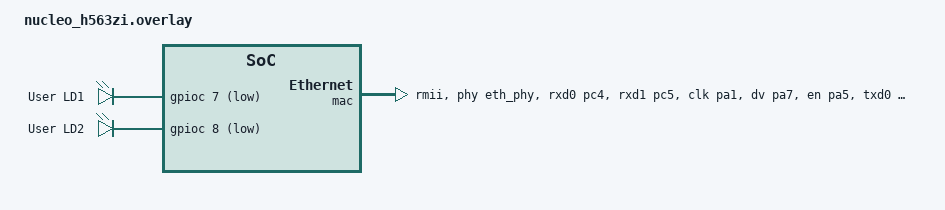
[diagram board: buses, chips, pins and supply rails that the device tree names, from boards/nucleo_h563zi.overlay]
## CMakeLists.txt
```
# SPDX-License-Identifier: Apache-2.0

cmake_minimum_required(VERSION 3.20.0)

find_package(Zephyr REQUIRED HINTS $ENV{ZEPHYR_BASE})
project(z_pub)

FILE(GLOB app_sources src/*.c)
target_sources(app PRIVATE ${app_sources})
```

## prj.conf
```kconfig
# printf, printk output to RTT
CONFIG_USE_SEGGER_RTT=y
CONFIG_RTT_CONSOLE=y
CONFIG_UART_CONSOLE=n
#CONFIG_SEGGER_RTT_MODE_NO_BLOCK_TRIM=y
#CONFIG_SEGGER_RTT_BUFFER_SIZE_UP=4096
#CONFIG_SEGGER_RTT_SECTION_CUSTOM_DTS_REGION=y

#
CONFIG_GPIO=y

# Increase stack size to 4096 bytes, otherwise it will crash with "Stack overflow in thread main"
CONFIG_MAIN_STACK_SIZE=4096
CONFIG_HEAP_MEM_POOL_SIZE=32768
CONFIG_POSIX_API=y

# Networking config
CONFIG_NETWORKING=y
CONFIG_NET_IPV4=y
CONFIG_NET_IPV6=y
CONFIG_NET_TCP=y
CONFIG_NET_UDP=y
CONFIG_NET_SOCKETS=y
CONFIG_NET_IPV4_MAPPING_TO_IPV6=y
CONFIG_NET_IPV4_IGMP=y

# Network address config
CONFIG_NET_CONFIG_SETTINGS=y
CONFIG_NET_CONFIG_NEED_IPV4=y
CONFIG_NET_CONFIG_NEED_IPV6=y
CONFIG_NET_CONFIG_MY_IPV4_ADDR="192.0.2.1"
CONFIG_NET_CONFIG_PEER_IPV4_ADDR="192.0.2.2"
CONFIG_NET_CONFIG_MY_IPV6_ADDR="2001:db8::1"
CONFIG_NET_CONFIG_PEER_IPV6_ADDR="2001:db8::2"

# zenoh-pico
CONFIG_ZENOH_PICO=y
```

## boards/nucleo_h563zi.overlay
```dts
/ {
	aliases {
		led0 = &green_led_1;
        led1 = &red_led_1;
	};
};

&clk_hse {
	status = "disabled";
};

&clk_hsi {
	status = "okay";
};

&pll {
	status = "disabled";
};

&rcc {
	clocks = <&clk_hsi>;
	clock-frequency = <64000000>;
};

&leds {
    green_led_1: led_1 {
        gpios = <&gpioc 7 GPIO_ACTIVE_LOW>;
        label = "User LD1";
    };

	yellow_led_1: led_2 {
		status = "disabled";
	};

    red_led_1: led_3 {
        gpios = <&gpioc 8 GPIO_ACTIVE_LOW>;
        label = "User LD2";
    };
};

&mac {
	status = "okay";
	pinctrl-0 = <&eth_rxd0_pc4
		     &eth_rxd1_pc5
		     &eth_ref_clk_pa1
		     &eth_crs_dv_pa7
		     &eth_tx_en_pa5
		     &eth_txd0_pb12
		     &eth_txd1_pb15>;
	pinctrl-names = "default";
	phy-connection-type = "rmii";
	phy-handle = <&eth_phy>;
};
```

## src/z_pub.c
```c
//
// Copyright (c) 2022 ZettaScale Technology
//
// This program and the accompanying materials are made available under the
// terms of the Eclipse Public License 2.0 which is available at
// http://www.eclipse.org/legal/epl-2.0, or the Apache License, Version 2.0
// which is available at https://www.apache.org/licenses/LICENSE-2.0.
//
// SPDX-License-Identifier: EPL-2.0 OR Apache-2.0
//
// Contributors:
//   ZettaScale Zenoh Team, <zenoh@zettascale.tech>

#include <stdio.h>
#include <stdlib.h>
#include <string.h>
#include <unistd.h>
#include <zenoh-pico.h>

#define CLIENT_OR_PEER 0  // 0: Client mode; 1: Peer mode
#if CLIENT_OR_PEER == 0
#define MODE "client"
//#define LOCATOR ""  // If empty, it will scout
#define LOCATOR "tcp/192.0.2.2:7447"
#elif CLIENT_OR_PEER == 1
#define MODE "peer"
#define LOCATOR "udp/224.0.0.225:7447#iface=en0"
#else
#error "Unknown Zenoh operation mode. Check CLIENT_OR_PEER value."
#endif

#define KEYEXPR "demo/example/zenoh-pico-pub"
#define VALUE CONFIG_BOARD_TARGET" Pub from Zenoh-Pico!"

#if Z_FEATURE_PUBLICATION == 1
int main(int argc, char **argv) {
    sleep(5);

    // Initialize Zenoh Session and other parameters
    z_owned_config_t config;
    z_config_default(&config);
    zp_config_insert(z_loan_mut(config), Z_CONFIG_MODE_KEY, MODE);
    if (strcmp(LOCATOR, "") != 0) {
        if (strcmp(MODE, "client") == 0) {
            zp_config_insert(z_loan_mut(config), Z_CONFIG_CONNECT_KEY, LOCATOR);
        } else {
            zp_config_insert(z_loan_mut(config), Z_CONFIG_LISTEN_KEY, LOCATOR);
        }
    }

    // Open Zenoh session
    printf("Opening Zenoh Session...");
    z_owned_session_t s;
    if (z_open(&s, z_move(config), NULL) < 0) {
        printf("Unable to open session!\n");
        return -1;
    }
    printf("OK\n");

    // Start the receive and the session lease loop for zenoh-pico
    zp_start_read_task(z_loan_mut(s), NULL);
    zp_start_lease_task(z_loan_mut(s), NULL);

    printf("Declaring publisher for '%s'...", KEYEXPR);
    z_view_keyexpr_t ke;
    z_view_keyexpr_from_str_unchecked(&ke, KEYEXPR);
    z_owned_publisher_t pub;
    if (z_declare_publisher(z_loan(s), &pub, z_loan(ke), NULL) < 0) {
        printf("Unable to declare publisher for key expression!\n");
        return -1;
    }
    printf("OK\n");

    char buf[256];
    for (int idx = 0; 1; ++idx) {
        sleep(1);
        sprintf(buf, "[%4d] %s", idx, VALUE);
        printf("Putting Data ('%s': '%s')...\n", KEYEXPR, buf);

        // Create payload
        z_owned_bytes_t payload;
        z_bytes_copy_from_str(&payload, buf);

        z_publisher_put(z_loan(pub), z_move(payload), NULL);
    }

    printf("Closing Zenoh Session...");
    z_drop(z_move(pub));

    z_drop(z_move(s));
    printf("OK!\n");

    return 0;
}
#else
int main(void) {
    printf("ERROR: Zenoh pico was compiled without Z_FEATURE_PUBLICATION but this example requires it.\n");
    return -2;
}
#endif
```
